# IWRL6432 register map
File version: 1.0
CPU: CM4 1.0, other endian, MPU, FPU, 3 interrupt priority bits
Registers are 32-bit, read-write, reset 0x0 unless marked. A register's access mark holds for its fields unless they carry their own. Offsets are from the block's base; [hi:lo] are bit positions; {n}, {i} and the like mark numbered series.

## APP_CFG_QSPI
Base 0x78000000
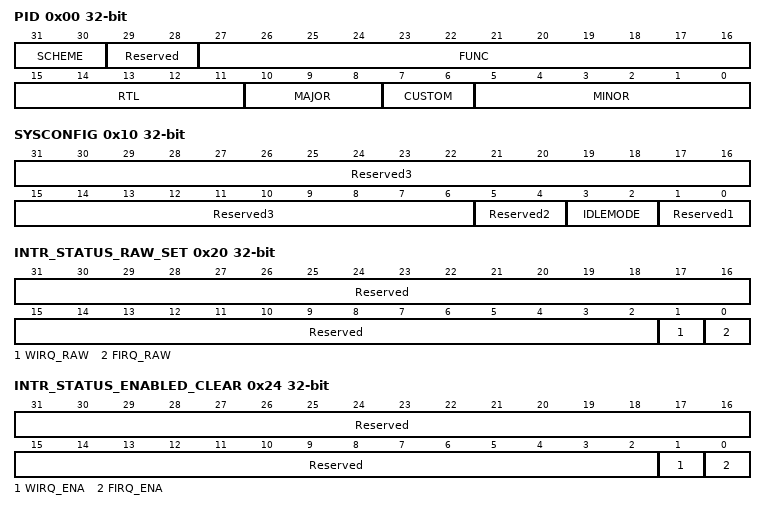
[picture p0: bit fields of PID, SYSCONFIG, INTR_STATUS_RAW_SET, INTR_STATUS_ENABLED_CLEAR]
0x00 PID
  [31:30] SCHEME — [31:30] The scheme of the register used. This indicates the PDR3.5 Method
  [29:28] Reserved — [29:28] Always read as 0
  [27:16] FUNC — [27:16] The function of the module being used
  [15:11] RTL — [15:11] RTL Release Version The PDR release number of this IP
  [10:8] MAJOR — [10:8] Major Release Number
  [7:6] CUSTOM — [7:6] Custom IP
  [5:0] MINOR — [5:0] Minor Release Number
{0x0+4i} MSS_QSPI_Reserved{i} (i=1..3) — Reserved
0x10 SYSCONFIG
  [31:6] Reserved3 — [31:6] Always read as 0
  [5:4] Reserved2 — [5:4] Always read as 0
  [3:2] IDLEMODE — [3:2] Configuration of the local target state management mode. By definition, target can handle read/write transaction as long as it is out of IDLE state 0x0 : Force-idle mode: local target's idle state follows (acknowledges) the system's idle requests unconditionally, i.e. regardless of the IP module's internal requirements. Backup mode, for debug only 0x1 : No-idle mode: local target never enters idle state. Backup mode, for debug only 0x2 : Smart-idle mode: local target's idle state eventually follows (acknowledges) the system's idle requests, depending on the IP module's internal requirements. IP module shall not generate (IRQ- or DMA-request-related) wakeup events 0x3 : Smart-idle wakeup-capable mode: local target's idle state eventually follows (acknowledges) the system's idle requests, depending on the IP module's internal requirements. IP module may generate (IRQ- or DMA-request-related) wakeup events when in idle state. Mode is only relevant if the appropriate IP module "swakeup" output(s) is (are) implemented
  [1:0] Reserved1 — [1:0] Always read as 0
{0x4+4i} MSS_QSPI_Reserved{i} (i=4..6) — Reserved
0x20 INTR_STATUS_RAW_SET — INTR Interrupt Status Raw/Set Register
  [31:2] Reserved — [31:2] Always read as 0
  [1] WIRQ_RAW — [1:1] Word Interrupt Status Read indicates raw status 0 = inactive 1 = active Writing 1 will set status Writing 0 has no effect
  [0] FIRQ_RAW — [0:0] Frame Interrupt Status Read indicates raw status 0 = inactive 1 = active Writing 1 will set status Writing 0 has no effect
0x24 INTR_STATUS_ENABLED_CLEAR — INTR Interrupt Status Enabled/Clear Register
  [31:2] Reserved — [31:2] Always read as 0
  [1] WIRQ_ENA — [1:1] Word Interrupt Enabled Status Read indicates enabled status 0 = inactive 1 = active Writing 1 will clear interrupt Writing 0 has no effect
  [0] FIRQ_ENA — [0:0] Frame Interrupt Enabled Status Read indicates enabled status 0 = inactive 1 = active Writing 1 will clear interrupt Writing 0 has no effect
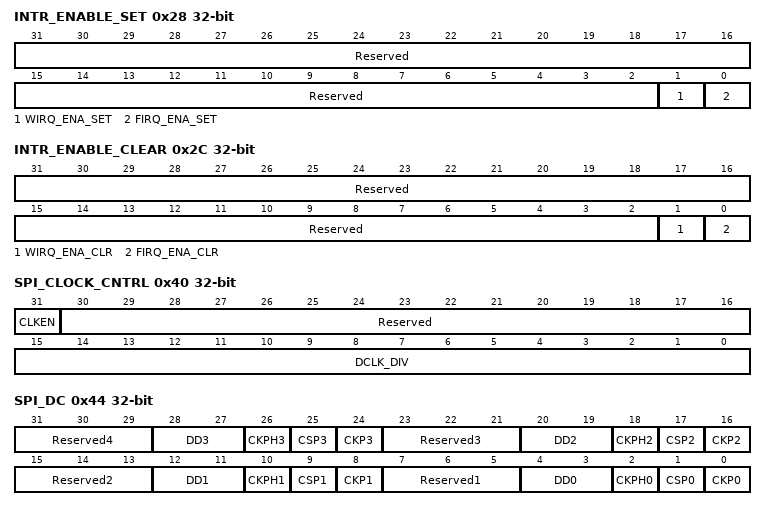
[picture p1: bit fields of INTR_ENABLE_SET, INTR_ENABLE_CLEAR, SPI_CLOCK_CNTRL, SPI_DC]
0x28 INTR_ENABLE_SET — INTR Interrupt Enable/Set Register
  [31:2] Reserved — [31:2] Always read as 0
  [1] WIRQ_ENA_SET — [1:1] Word Interrupt Enable/Set Read indicates interrupt enable 0 = disabled 1 = enabled Writing 1 will set interrupt enabled Writing 0 has no effect
  [0] FIRQ_ENA_SET — [0:0] Frame Interrupt Enable/Set Read indicates interrupt enable 0 = disabled 1 = enabled Writing 1 will set interrupt enabled Writing 0 has no effect
0x2C INTR_ENABLE_CLEAR — INTR Interrupt Enable/Clear Register
  [31:2] Reserved — [31:2] Always read as 0
  [1] WIRQ_ENA_CLR — [1:1] Word Interrupt Enable/Clear Read indicates interrupt enable 0 = disabled 1 = enabled Writing 1 will clear interrupt enabled Writing 0 has no effect
  [0] FIRQ_ENA_CLR — [0:0] Frame Interrupt Enable/Clear Read indicates interrupt enable 0 = disabled 1 = enabled Writing 1 will clear interrupt enabled Writing 0 has no effect
0x30 INTC_EOI — EOI Register
  [31:0] EOI_VECTOR — [31:0] Number associated with the ipgenericirq for intr output. There are 1 interrupt outputs Write 0x0 : Write to intr IP Generic Any other write value is ignored.
{0x18+4i} MSS_QSPI_Reserved{i} (i=7..9) — Reserved
0x40 SPI_CLOCK_CNTRL — SPI Clock Control Register (SPICC)
  [31] CLKEN — [31:31] Clock Enable. 0- Data clock is turned off 1- Data clock is enabled
  [30:16] Reserved — [30:16] Always read as 0
  [15:0] DCLK_DIV — [15:0] Serial data clock divide by ratio
0x44 SPI_DC — SPI Data Control Register (SPIDC)
  [8n-1:8n-3] Reserved{n} (n=1..4) — [{8n-1}:{8n-3}] Always read as 0
  [8n+4:8n+3] DD{n} (n=0..3) — [{8n+4}:{8n+3}] Data delay for chip select {n} 00- Data is output on the same cycle as the CS_N goes active 01- Data is output 1 DCLK cycle after the CS_N goes active 10- Data is output 2 DCLK cycles after the CS_N goes active 11- Data is output 3 DCLK cycles after the CS_N goes active
  [26] CKPH3 — [26:26] Clock phase for chip select 3 If CKP0 = 0 0- Data shifted out on falling edge; input on rising edge 1- Data shifted out on rising edge; input on falling edge If CKP0 = 1 1- Data shifted out on falling edge; input on rising edge 0- Data shifted out on rising edge; input on falling edge
  [8n+1] CSP{n} (n=0..3) — [{8n+1}:{8n+1}] Chip select polarity for chip select {n} 0- Active low 1- Active high
  [8n] CKP{n} (n=0..3) — [{8n}:{8n}] Clock polarity for chip select {n} 0- When data is not being transferred, SCK = 0 1- When data is not being transferred, SCK = 1
  [18] CKPH2 — [18:18] Clock phase for chip select 2. If CKP0 = 0 0- Data shifted out on falling edge; input on rising edge 1- Data shifted out on rising edge; input on falling edge If CKP0 = 1 1- Data shifted out on falling edge; input on rising edge 0- Data shifted out on rising edge; input on falling edge
  [10] CKPH1 — [10:10] Clock phase for chip select 1. If CKP0 = 0 0- Data shifted out on falling edge; input on rising edge 1- Data shifted out on rising edge; input on falling edge If CKP0 = 1 1- Data shifted out on falling edge; input on rising edge 0- Data shifted out on rising edge; input on falling edge
  [2] CKPH0 — [2:2] Clock phase for chip select 0. If CKP0 = 0 0- Data shifted out on falling edge; input on rising edge 1- Data shifted out on rising edge; input on falling edge If CKP0 = 1 1- Data shifted out on falling edge; input on rising edge 0- Data shifted out on rising edge; input on falling edge
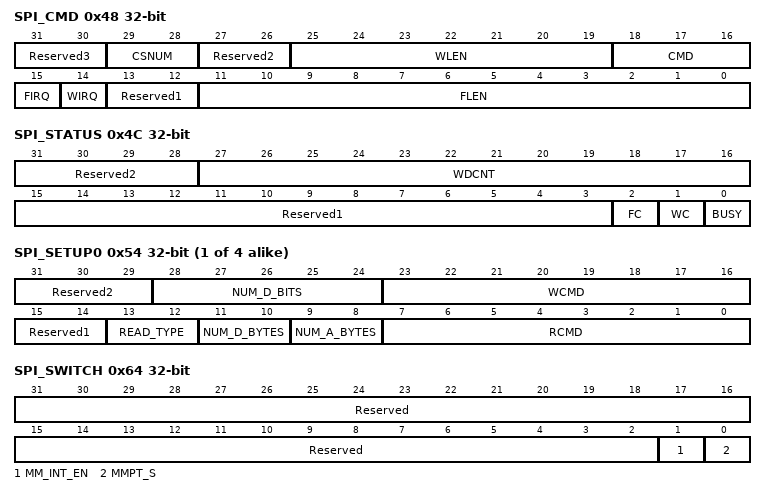
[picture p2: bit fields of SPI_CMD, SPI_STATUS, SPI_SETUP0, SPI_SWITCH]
0x48 SPI_CMD — SPI Command Register (SPICR)
  [31:30] Reserved3 — [31:30] Always read as 0
  [29:28] CSNUM — [29:28] Device select. Sets the active chip select for the transfer 00- Chip Select 0 active 01- Chip Select 1 active 10- Chip Select 2 active 11- Chip Select 3 active
  [27:26] Reserved2 — [27:26] Always read as 0
  [25:19] WLEN — [25:19] Word length. Sets the size of the individual transfers from 1 ΓÇô 128 bits 0- 1 bit 1- 2 bits ΓÇª 127 ΓÇô 128 bits
  [18:16] CMD — [18:16] Transfer command 000- Reserved 001- 4 pin Read Single 010- 4 pin Write Single 011- 4 pin Read Dual 100 ΓÇô Reserved 101 ΓÇô 3 pin Read Single 110 ΓÇô 3 pin Write Single 111 ΓÇô 6 pin Read Quad
  [15] FIRQ — [15:15] Frame count interrupt enable
  [14] WIRQ — [14:14] Word count interrupt enable
  [13:12] Reserved1 — [13:12] Always read as 0
  [11:0] FLEN — [11:0] Frame Length 0- 1 word 1- 2 words ΓÇª 4095 ΓÇô 4096 words
0x4C SPI_STATUS — SPI Status Register (SPISR)
  [31:28] Reserved2 — [31:28] Always read as 0
  [27:16] WDCNT — [27:16] Word count. This field will reflect the 1-4096 words transferred
  [15:3] Reserved1 — [15:3] Always read as 0
  [2] FC — [2:2] Frame complete. This bit is set after all of the requested words have been transmitted. 0- Transfer is not complete 1- Transfer is complete This bit is reset when the SPI Status Register is read
  [1] WC — [1:1] Word complete. This bit is set after each word transfer is completed. 0- Word transfer is not complete 1- Word transfer is complete This bit is reset when the SPI Status Register is read
  [0] BUSY — [0:0] Busy bit. Active transfer in progress. This bit is only set during an active word transfer. Between words, the bit will clear to signal that it is ok to read/write the data registers. 0- Idle 1- Busy
0x50 SPI_DATA — SPI Data Register (SPIDR)
  [31:0] DATA — [31:0] Data register for read and write operations
{0x54+4i} SPI_SETUP{i} (i=0..3) — Memory Mapped SPI Setup{i} Register
  [31:29] Reserved2 — [31:29] Always read as 0
  [28:24] NUM_D_BITS — [28:24] Number of dummy bits to use if NUM_D_BYTES = 0
  [23:16] WCMD — [23:16] Write Command
  [15:14] Reserved1 — [15:14] Always read as 0
  [13:12] READ_TYPE — [13:12] Determines if the read command is a single, dual or quad read mode command 00 ΓÇô Normal read (all data input on spi_din) 01 ΓÇô Dual read (odd bytes input on spi_din; even on spi_dout) 10 ΓÇô Normal read (all data input on spi_din) 11 ΓÇô Quad read (uses spi_qdin0/1)
  [11:10] NUM_D_BYTES — [11:10] Number of dummy bytes to be used for fast read. 0 = use the value in NUM_D_BITS 1 = use 8 bits; 2 = use 16 bits; 3 = use 24 bits
  [9:8] NUM_A_BYTES — [9:8] Number of address bytes to be sent. 0 = 1 byte; 1 = 2 bytes; 2 = 3 bytes; 3 = 4 bytes
  [7:0] RCMD — [7:0] Read Command
0x64 SPI_SWITCH — Memory Mapped SPI Switch Register
  [31:2] Reserved — [31:2] Always read as 0
  [1] MM_INT_EN — [1:1] Memory Mapped mode interrupt enable. 0 ΓÇô Interrupts are disabled during memory mapped operations 1 ΓÇô Word Count interrupt is enabled for memory mapped operations
  [0] MMPT_S — [0:0] MMPT select. If 0 (default) config port has is selected to control config of core SPI module. If 1, Memory Mapped Protocol Translator is selected to control config port of core SPI module.
{0x64+4i} SPI_DATA{i} (i=1..3) — SPI Data Register (SPIDR{i})
  [31:0] DATA — [31:0] Data register for read and write operations
